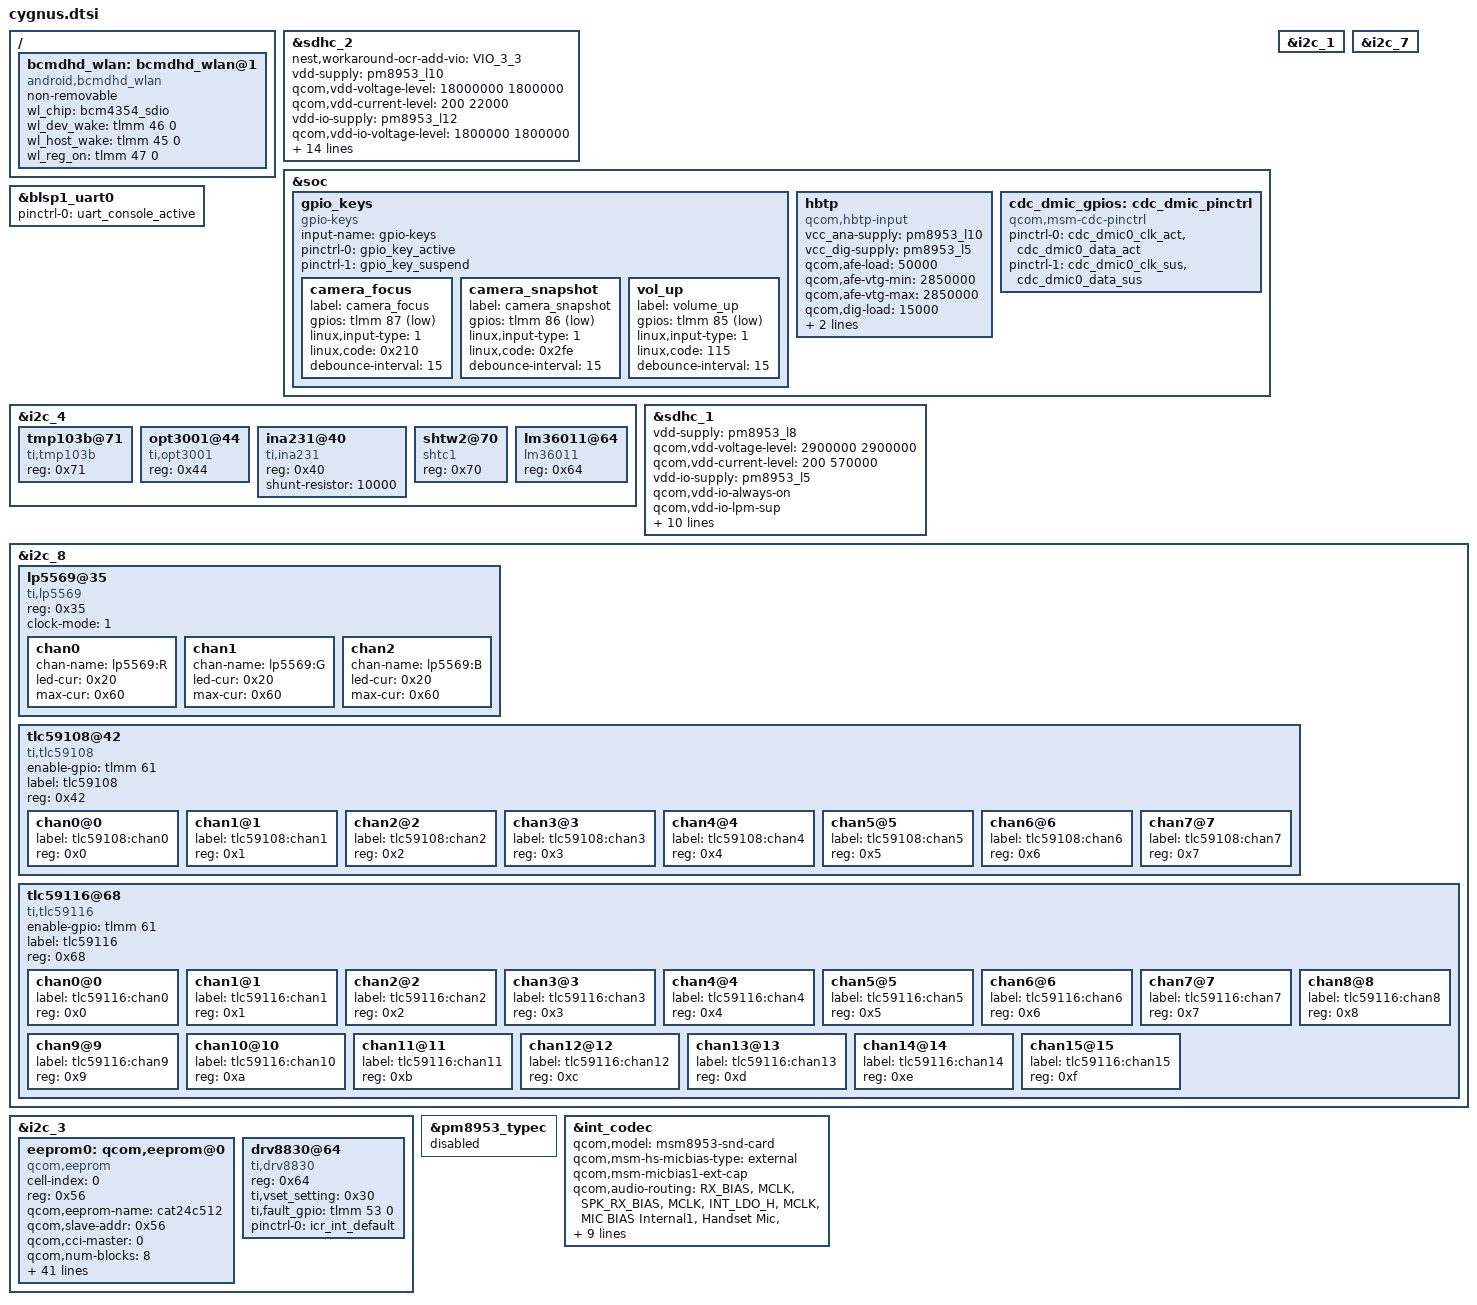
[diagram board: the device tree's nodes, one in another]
/ {
	bcmdhd_wlan: bcmdhd_wlan@1 {
		compatible = "android,bcmdhd_wlan";
		non-removable;
		wl_chip = "bcm4354_sdio";
		wl_dev_wake = <&tlmm 46 0>;     /* WIFI_DEV_WAKE */
		wl_host_wake = <&tlmm 45 0>;    /* WIFI_WL_HOST_WAKE */
		wl_reg_on = <&tlmm 47 0>;       /* WIFI_WL_REG_ON */
	};
};

&sdhc_2 {
	nest,workaround-ocr-add-vio = "VIO_3_3";
};

&soc {
	gpio_keys {
		compatible = "gpio-keys";
		input-name = "gpio-keys";
		pinctrl-names = "tlmm_gpio_key_active","tlmm_gpio_key_suspend";
		pinctrl-0 = <&gpio_key_active>;
		pinctrl-1 = <&gpio_key_suspend>;

		camera_focus {
			label = "camera_focus";
			gpios = <&tlmm 87 0x1>;
			linux,input-type = <1>;
			linux,code = <0x210>;
			debounce-interval = <15>;
		};

		camera_snapshot {
			label = "camera_snapshot";
			gpios = <&tlmm 86 0x1>;
			linux,input-type = <1>;
			linux,code = <0x2fe>;
			debounce-interval = <15>;
		};

		vol_up {
			label = "volume_up";
			gpios = <&tlmm 85 0x1>;
			linux,input-type = <1>;
			linux,code = <115>;
			debounce-interval = <15>;
		};
	};

	hbtp {
		compatible = "qcom,hbtp-input";
		vcc_ana-supply = <&pm8953_l10>;
		vcc_dig-supply = <&pm8953_l5>;
		qcom,afe-load = <50000>;
		qcom,afe-vtg-min = <2850000>;
		qcom,afe-vtg-max = <2850000>;
		qcom,dig-load = <15000>;
		qcom,dig-vtg-min = <1800000>;
		qcom,dig-vtg-max = <1800000>;
	};

	cdc_dmic_gpios: cdc_dmic_pinctrl {
		compatible = "qcom,msm-cdc-pinctrl";
		pinctrl-names = "aud_active", "aud_sleep";
		pinctrl-0 = <&cdc_dmic0_clk_act &cdc_dmic0_data_act>;
		pinctrl-1 = <&cdc_dmic0_clk_sus &cdc_dmic0_data_sus>;
	};
};

&blsp1_uart0 {
	status = "ok";
	pinctrl-names = "default";
	pinctrl-0 = <&uart_console_active>;
};

/* Enable for coprocessor */
&i2c_1 {
	status = "ok";
};

&i2c_4 {
	status = "ok";
	tmp103b@71 {
		compatible = "ti,tmp103b";
		reg = <0x71>;
	};

	opt3001@44 {
		compatible = "ti,opt3001";
		reg = <0x44>; /* ALS_ADDR connected to ground */
		status = "okay";
	};

	ina231@40 {
		compatible = "ti,ina231";
		reg = <0x40>;
		shunt-resistor = <10000>;
	};

	shtw2@70 {
		compatible = "shtc1";
		reg = <0x70>;
	};

	lm36011@64 {
		compatible = "lm36011";
		reg = <0x64>;
	};
};

/* Enable for coprocessor PMIC */
&i2c_7 {
	status = "ok";
};

&sdhc_1 {
	/* device core power supply */
	vdd-supply = <&pm8953_l8>;
	qcom,vdd-voltage-level = <2900000 2900000>;
	qcom,vdd-current-level = <200 570000>;

	/* device communication power supply */
	vdd-io-supply = <&pm8953_l5>;
	qcom,vdd-io-always-on;
	qcom,vdd-io-lpm-sup;
	qcom,vdd-io-voltage-level = <1800000 1800000>;
	qcom,vdd-io-current-level = <200 325000>;

	pinctrl-names = "active", "sleep";
	pinctrl-0 = <&sdc1_clk_on &sdc1_cmd_on &sdc1_data_on  &sdc1_rclk_on>;
	pinctrl-1 = <&sdc1_clk_off &sdc1_cmd_off &sdc1_data_off &sdc1_rclk_off>;

	qcom,clk-rates = <400000 20000000 25000000 50000000 100000000 192000000
								384000000>;
	qcom,nonremovable;
	qcom,bus-speed-mode = "HS200_1p8v";

	status = "ok";
};

&i2c_8 {
	status = "ok";
	lp5569@35 {
		compatible = "ti,lp5569";
		reg = <0x35>;
		clock-mode = /bits/8 <1>;
		chan0 {
			chan-name = "lp5569:R";
			led-cur = /bits/ 8 <0x20>;
			max-cur = /bits/ 8 <0x60>;
		};

		chan1 {
			chan-name = "lp5569:G";
			led-cur = /bits/ 8 <0x20>;
			max-cur = /bits/ 8 <0x60>;
		};

		chan2 {
			chan-name = "lp5569:B";
			led-cur = /bits/ 8 <0x20>;
			max-cur = /bits/ 8 <0x60>;
		};

	};

	tlc59108@42 {
		#address-cells = <1>;
		#size-cells = <0>;
		#gpio-cells = <2>;
		enable-gpio = <&tlmm 61 GPIO_ACTIVE_HIGH>;
		compatible = "ti,tlc59108";
		label = "tlc59108";
		reg = <0x42>;

		chan0@0 {
			label = "tlc59108:chan0";
			reg = <0x0>;
		};

		chan1@1 {
			label = "tlc59108:chan1";
			reg = <0x1>;
		};

		chan2@2 {
			label = "tlc59108:chan2";
			reg = <0x2>;
		};

		chan3@3 {
			label = "tlc59108:chan3";
			reg = <0x3>;
		};

		chan4@4 {
			label = "tlc59108:chan4";
			reg = <0x4>;
		};

		chan5@5 {
			label = "tlc59108:chan5";
			reg = <0x5>;
		};

		chan6@6 {
			label = "tlc59108:chan6";
			reg = <0x6>;
		};

		chan7@7 {
			label = "tlc59108:chan7";
			reg = <0x7>;
		};
	};

	tlc59116@68 {
		#address-cells = <1>;
		#size-cells = <0>;
		#gpio-cells = <2>;
		enable-gpio = <&tlmm 61 GPIO_ACTIVE_HIGH>;
		compatible = "ti,tlc59116";
		label = "tlc59116";
		reg = <0x68>;

		chan0@0 {
			label = "tlc59116:chan0";
			reg = <0x0>;
		};

		chan1@1 {
			label = "tlc59116:chan1";
			reg = <0x1>;
		};

		chan2@2 {
			label = "tlc59116:chan2";
			reg = <0x2>;
		};

		chan3@3 {
			label = "tlc59116:chan3";
			reg = <0x3>;
		};

		chan4@4 {
			label = "tlc59116:chan4";
			reg = <0x4>;
		};

		chan5@5 {
			label = "tlc59116:chan5";
			reg = <0x5>;
		};

		chan6@6 {
			label = "tlc59116:chan6";
			reg = <0x6>;
		};

		chan7@7 {
			label = "tlc59116:chan7";
			reg = <0x7>;
		};

		chan8@8 {
			label = "tlc59116:chan8";
			reg = <0x8>;
		};

		chan9@9 {
			label = "tlc59116:chan9";
			reg = <0x9>;
		};

		chan10@10 {
			label = "tlc59116:chan10";
			reg = <0xa>;
		};

		chan11@11 {
			label = "tlc59116:chan11";
			reg = <0xb>;
		};

		chan12@12 {
			label = "tlc59116:chan12";
			reg = <0xc>;
		};

		chan13@13 {
			label = "tlc59116:chan13";
			reg = <0xd>;
		};

		chan14@14 {
			label = "tlc59116:chan14";
			reg = <0xe>;
		};

		chan15@15 {
			label = "tlc59116:chan15";
			reg = <0xf>;
		};
	};

};

&i2c_3 {
	status = "ok";
	eeprom0: qcom,eeprom@0 {
		cell-index = <0>;
		reg = <0x56>;
		qcom,eeprom-name = "cat24c512";
		compatible = "qcom,eeprom";
		qcom,slave-addr = <0x56>;
		qcom,cci-master = <0>;
		/* For 512 Kb eeprom chip
		add 8 logic eeprom blcoks each is 8KB*/
		qcom,num-blocks = <8>;

		qcom,page0 = <0 0 0 0 0 0>;
		qcom,poll0 = <0 0 0 0 0 0>;
		qcom,saddr0 = <0x56>;
		qcom,mem0 = <8192 0x0000 2 0 1 0>;

		qcom,page1 = <0 0 0 0 0 0>;
		qcom,poll1 = <0 0 0 0 0 0>;
		qcom,saddr1 = <0x56>;
		qcom,mem1 = <8192 0x2000 2 0 1 0>;

		qcom,page2 = <0 0 0 0 0 0>;
		qcom,poll2 = <0 0 0 0 0 0>;
		qcom,saddr2 = <0x56>;
		qcom,mem2 = <8192 0x4000 2 0 1 0>;

		qcom,page3 = <0 0 0 0 0 0>;
		qcom,poll3 = <0 0 0 0 0 0>;
		qcom,saddr3 = <0x56>;
		qcom,mem3 = <8192 0x6000 2 0 1 0>;

		qcom,page4 = <0 0 0 0 0 0>;
		qcom,poll4 = <0 0 0 0 0 0>;
		qcom,saddr4 = <0x56>;
		qcom,mem4 = <8192 0x8000 2 0 1 0>;

		qcom,page5 = <0 0 0 0 0 0>;
		qcom,poll5 = <0 0 0 0 0 0>;
		qcom,saddr5 = <0x56>;
		qcom,mem5 = <8192 0xA000 2 0 1 0>;

		qcom,page6 = <0 0 0 0 0 0>;
		qcom,poll6 = <0 0 0 0 0 0>;
		qcom,saddr6 = <0x56>;
		qcom,mem6 = <8192 0xC000 2 0 1 0>;

		qcom,page7 = <0 0 0 0 0 0>;
		qcom,poll7 = <0 0 0 0 0 0>;
		qcom,saddr7 = <0x56>;
		qcom,mem7 = <8192 0xE000 2 0 1 0>;

		cam_vio-supply = <&pm8953_l6>;
		qcom,cam-vreg-name = "cam_vio";
		qcom,cam-vreg-min-voltage = <0>;
		qcom,cam-vreg-max-voltage = <0>;
		qcom,cam-vreg-op-mode = <0>;
		qcom,cam-power-seq-type = "sensor_vreg";
		qcom,cam-power-seq-val = "cam_vio";
		qcom,cam-power-seq-cfg-val = <1>;
		qcom,cam-power-seq-delay = <1>;
		status = "ok";
	};

	drv8830@64 {
		compatible = "ti,drv8830";
		reg = <0x64>;
		ti,vset_setting = <0x30>; /* 0x30 translates to 3.86v */
		ti,fault_gpio = <&tlmm 53 0>;
		pinctrl-names = "default";
		pinctrl-0 = <&icr_int_default>;
		status = "okay";
	};
};

&sdhc_2 {
	/* device core power supply */
	vdd-supply = <&pm8953_l10>;
	qcom,vdd-voltage-level = <18000000 1800000>;
	qcom,vdd-current-level = <200 22000>;

	/* device communication power supply */
	vdd-io-supply = <&pm8953_l12>;
	qcom,vdd-io-voltage-level = <1800000 1800000>;
	qcom,vdd-io-current-level = <200 22000>;

	pinctrl-names = "active", "sleep";
	pinctrl-0 = <&sdc2_clk_on &sdc2_cmd_on &sdc2_data_on>;
	pinctrl-1 = <&sdc2_clk_off &sdc2_cmd_off &sdc2_data_off>;

	#address-cells = <0>;
	interrupt-parent = <&sdhc_2>;
	interrupts = <0 1 2>;
	#interrupt-cells = <1>;
	interrupt-map-mask = <0xffffffff>;
	interrupt-map = <0 &intc 0 125 0
		1 &intc 0 221 0
		2 &tlmm 45 0>;
	interrupt-names = "hc_irq", "pwr_irq", "sdiowakeup_irq";
	/*cd-gpios = <&tlmm 45 0x1>;*/

	qcom,clk-rates = <400000 20000000 25000000 50000000 100000000
								200000000>;
	qcom,bus-speed-mode = "SDR12", "SDR25", "SDR50", "DDR50", "SDR104";

	status = "ok";
};

&pm8953_typec {
	status = "disabled";
};

&int_codec {
	status = "ok";
	qcom,model = "msm8953-snd-card";
	qcom,msm-hs-micbias-type = "external";
	qcom,msm-micbias1-ext-cap;

	qcom,audio-routing =
		"RX_BIAS", "MCLK",
		"SPK_RX_BIAS", "MCLK",
		"INT_LDO_H", "MCLK",
		"MIC BIAS Internal1", "Handset Mic",
		"MIC BIAS Internal2", "Headset Mic",
		"MIC BIAS Internal1", "Secondary Mic",
		"AMIC1", "MIC BIAS Internal1",
		"AMIC2", "MIC BIAS Internal2",
		"AMIC3", "MIC BIAS Internal1",
		"DMIC1", "MIC BIAS Internal1",
		"MIC BIAS Internal1", "Digital Mic1",
		"DMIC2", "MIC BIAS Internal1",
		"MIC BIAS Internal1", "Digital Mic2";

	qcom,cdc-dmic-gpios = <&cdc_dmic_gpios>;
};

